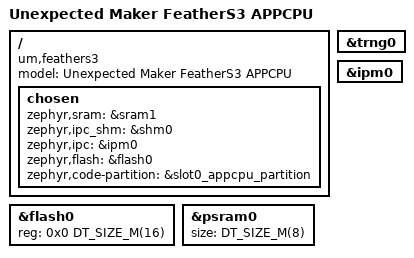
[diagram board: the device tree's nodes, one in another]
/*
 * SPDX-FileCopyrightText: Copyright (c) 2024 Espressif Systems (Shanghai) Co., Ltd.
 * SPDX-FileCopyrightText: Copyright (c) 2024 Leon Rinkel <leon@rinkel.me>
 * SPDX-FileCopyrightText: Copyright (c) 2026 Perry Naseck, MIT Media Lab <pnaseck@media.mit.edu>
 * SPDX-License-Identifier: Apache-2.0
 */
/dts-v1/;

#include <espressif/esp32s3/esp32s3.dtsi>
#include <espressif/partitions_0x0_amp_16M.dtsi>
#include "um_feathers3-pinctrl.dtsi"

/ {
	compatible = "um,feathers3", "espressif,esp32s3";
	model = "Unexpected Maker FeatherS3 APPCPU";

	chosen {
		zephyr,sram = &sram1;
		zephyr,ipc_shm = &shm0;
		zephyr,ipc = &ipm0;
		zephyr,flash = &flash0;
		zephyr,code-partition = &slot0_appcpu_partition;
	};
};

&flash0 {
	reg = <0x0 DT_SIZE_M(16)>;
	ranges = <0x0 0x0 DT_SIZE_M(16)>;
};

&psram0 {
	size = <DT_SIZE_M(8)>;
};

&trng0 {
	status = "okay";
};

&ipm0 {
	status = "okay";
};
